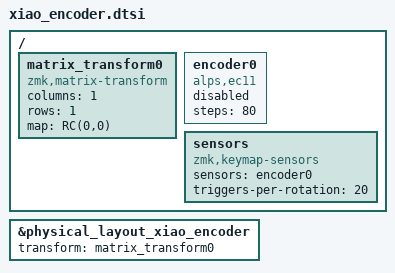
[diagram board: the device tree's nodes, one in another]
#include "xiao_encoder-layouts.dtsi"
#include <dt-bindings/zmk/matrix_transform.h>

/ {
    matrix_transform0: matrix_transform0 {
        compatible = "zmk,matrix-transform";
        columns = <1>;
        rows = <1>;
        map = <
            RC(0,0)
        >;
    };
};

&physical_layout_xiao_encoder {
    transform = <&matrix_transform0>;
};

// Encoders for all parts of the keyboard.
// If the encoder(s) are not behaving as expected,
// update steps and triggers-per-rotation to match your hardware.
// All pin assignments are done in the part overlays.

/ {
    encoder0: encoder0 {
        compatible = "alps,ec11";
        steps = <80>;
        status = "disabled";
    };

    sensors: sensors {
        compatible = "zmk,keymap-sensors";
        sensors = <&encoder0>;
        triggers-per-rotation = <20>;
    };
};

